# RE01_1500KB register map
Vendor: Renesas Electronics Corporation; Series: RE01_1500KB; File version: 1.20
CPU: CM0PLUS r0p1, little endian, MPU, no FPU, VTOR, 2 interrupt priority bits
Registers are 8-bit, read-write, reset 0x0 unless marked. A register's access mark holds for its fields unless they carry their own. Offsets are from the block's base; [hi:lo] are bit positions; {n}, {i} and the like mark numbered series; 'fields as' and 'values as' point back to an identical list; <NAME> marks a mode.

## GPT162 — General PWM Timer 2 (16-bit)
Base 0x40055200
Same registers: GPT163 0x40055300, GPT164 0x40055400, GPT165 0x40055500
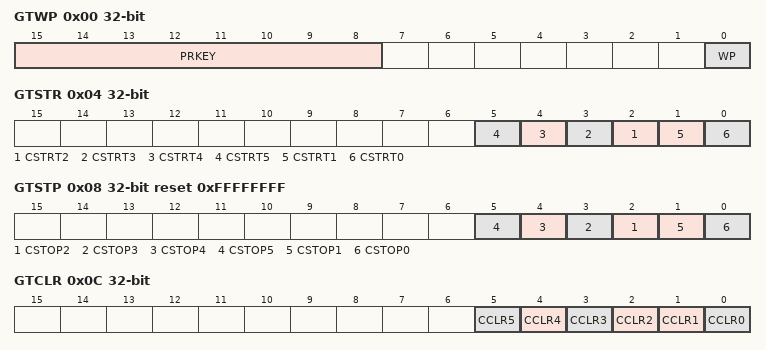
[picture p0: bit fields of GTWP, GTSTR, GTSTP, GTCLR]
0x00 GTWP 32-bit — General PWM Timer Write-Protection Register
  [15:8] PRKEY wo — GTWP Key Code
    165=Written to these bits, the WP bits write is permitted; other=others (The WP bits write is not permitted.)
  [0] WP — Register Write Disable
    0=Write to the register is enabled; 1=Write to the register is disabled
0x04 GTSTR 32-bit — General PWM Timer Software Start Register
  [n] CSTRT{n} (n=2..5) — Channel {n} GTCNT Count StartRead data shows each channel's counter status (GTCR.CST bit). 0 means counter stop. 1 means counter running.
    0=No effect (write) / counter stop (read); 1=GPT{n+160}.GTCNT counter starts (write) / Counter running (read)
  [1] CSTRT1 — Channel 1 GTCNT Count StartRead data shows each channel's counter status (GTCR.CST bit). 0 means counter stop. 1 means counter running.
    0=No effect (write) / counter stop (read); 1=GPT321.GTCNT counter starts (write) / Counter running (read)
  [0] CSTRT0 — Channel 0 GTCNT Count StartRead data shows each channel's counter status (GTCR.CST bit). 0 means counter stop. 1 means counter running.
    0=No effect (write) / counter stop (read); 1=GPT320.GTCNT counter starts (write) / Counter running (read)
0x08 GTSTP 32-bit reset 0xFFFFFFFF — General PWM Timer Software Stop Register
  [n] CSTOP{n} (n=2..5) — Channel {n} GTCNT Count StopRead data shows each channel's counter status (GTCR.CST bit). 0 means counter runnning. 1 means counter stop.
    0=No effect (write) / counter running (read); 1=GPT{n+160}.GTCNT counter stops (write) / Counter stop (read)
  [1] CSTOP1 — Channel 1 GTCNT Count StopRead data shows each channel's counter status (GTCR.CST bit). 0 means counter runnning. 1 means counter stop.
    0=No effect (write) / counter running (read); 1=GPT321.GTCNT counter stops (write) / Counter stop (read)
  [0] CSTOP0 — Channel 0 GTCNT Count StopRead data shows each channel's counter status (GTCR.CST bit). 0 means counter runnning. 1 means counter stop.
    0=No effect (write) / counter running (read); 1=GPT320.GTCNT counter stops (write) / Counter stop (read)
0x0C GTCLR 32-bit wo — General PWM Timer Software Clear Register
  [n] CCLR{n} (n=2..5) — Channel {n} GTCNT Count Clear
    0=No effect; 1=GPT{n+160}.GTCNT counter clears
  [1] CCLR1 — Channel 1 GTCNT Count Clear
    0=No effect; 1=GPT321.GTCNT counter clears
  [0] CCLR0 — Channel 0 GTCNT Count Clear
    0=No effect; 1=GPT320.GTCNT counter clears
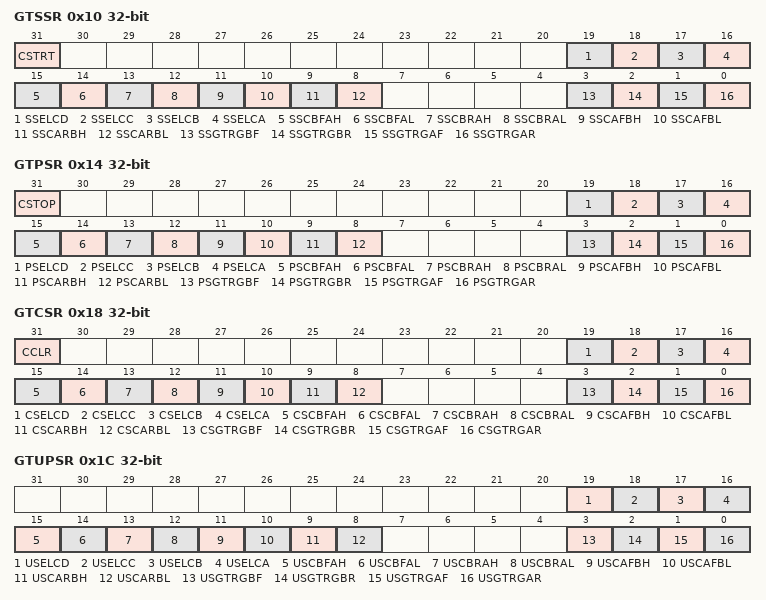
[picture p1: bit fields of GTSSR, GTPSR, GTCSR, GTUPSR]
0x10 GTSSR 32-bit — General PWM Timer Start Source Select Register
  [31] CSTRT — Software Source Counter Start Enable
    0=Counter start is disable by the GTSTR register; 1=Counter start is enable by the GTSTR register
  [19] SSELCD — ELCD Event Source Counter Start Enable
    0=Counter start is disable at the ELCD input; 1=Counter start is enable at the ELCD input
  [18] SSELCC — ELCC Event Source Counter Start Enable
    0=Counter start is disable at the ELCC input; 1=Counter start is enable at the ELCC input
  [17] SSELCB — ELCB Event Source Counter Start Enable
    0=Counter start is disable at the ELCB input; 1=Counter start is enable at the ELCB input
  [16] SSELCA — ELCA Event Source Counter Start Enable
    0=Counter start is disable at the ELCA input; 1=Counter start is enable at the ELCA input
  [15] SSCBFAH — GTIOCB Pin Falling Input during GTIOCA Value High Source Counter Start Enable
    0=Counter start is disable at the falling edge of GTIOCB input when GTIOCA input is 1; 1=Counter start is enable at the falling edge of GTIOCB input when GTIOCA input is 1
  [14] SSCBFAL — GTIOCB Pin Falling Input during GTIOCA Value Low Source Counter Start Enable
    0=Counter start is disable at the falling edge of GTIOCB input when GTIOCA input is 0; 1=Counter start is enable at the falling edge of GTIOCB input when GTIOCA input is 0
  [13] SSCBRAH — GTIOCB Pin Rising Input during GTIOCA Value High Source Counter Start Enable
    0=Counter start is disable at the rising edge of GTIOCB input when GTIOCA input is 1; 1=Counter start is enable at the rising edge of GTIOCB input when GTIOCA input is 1
  [12] SSCBRAL — GTIOCB Pin Rising Input during GTIOCA Value Low Source Counter Start Enable
    0=Counter start is disable at the rising edge of GTIOCB input when GTIOCA input is 0; 1=Counter start is enable at the rising edge of GTIOCB input when GTIOCA input is 0
  [11] SSCAFBH — GTIOCA Pin Falling Input during GTIOCB Value High Source Counter Start Enable
    0=Counter start is disable at the falling edge of GTIOCA input when GTIOCB input is 1; 1=Counter start is enable at the falling edge of GTIOCA input when GTIOCB input is 1
  [10] SSCAFBL — GTIOCA Pin Falling Input during GTIOCB Value Low Source Counter Start Enable
    0=Counter start is disable at the falling edge of GTIOCA input when GTIOCB input is 0; 1=Counter start is enable at the falling edge of GTIOCA input when GTIOCB input is 0
  [9] SSCARBH — GTIOCA Pin Rising Input during GTIOCB Value High Source Counter Start Enable
    0=Counter start is disable at the rising edge of GTIOCA input when GTIOCB input is 1; 1=Counter start is enable at the rising edge of GTIOCA input when GTIOCB input is 1
  [8] SSCARBL — GTIOCA Pin Rising Input during GTIOCB Value Low Source Counter Start Enable
    0=Counter start is disable at the rising edge of GTIOCA input when GTIOCB input is 0; 1=Counter start is enable at the rising edge of GTIOCA input when GTIOCB input is 0
  [3] SSGTRGBF — GTETRGB Pin Falling Input Source Counter Start Enable
    0=Counter start is disable at the falling edge of GTETRGB input; 1=Counter start is enable at the falling edge of GTETRGB input
  [2] SSGTRGBR — GTETRGB Pin Rising Input Source Counter Start Enable
    0=Counter start is disable at the rising edge of GTETRGB input; 1=Counter start is enable at the rising edge of GTETRGB input
  [1] SSGTRGAF — GTETRGA Pin Falling Input Source Counter Start Enable
    0=Counter start is disable at the falling edge of GTETRGA input; 1=Counter start is enable at the falling edge of GTETRGA input
  [0] SSGTRGAR — GTETRGA Pin Rising Input Source Counter Start Enable
    0=Counter start is disable at the rising edge of GTETRGA input; 1=Counter start is enable at the rising edge of GTETRGA input
0x14 GTPSR 32-bit — General PWM Timer Stop Source Select Register
  [31] CSTOP — Software Source Counter Stop Enable
    0=Counter stop is disable by the GTSTP register; 1=Counter stop is enable by the GTSTP register
  [19] PSELCD — ELCD Event Source Counter Stop Enable
    0=Counter stop is disable at the ELCD input; 1=Counter stop is enable at the ELCD input
  [18] PSELCC — ELCC Event Source Counter Stop Enable
    0=Counter stop is disable at the ELCC input; 1=Counter stop is enable at the ELCC input
  [17] PSELCB — ELCB Event Source Counter Stop Enable
    0=Counter stop is disable at the ELCB input; 1=Counter stop is enable at the ELCB input
  [16] PSELCA — ELCA Event Source Counter Stop Enable
    0=Counter stop is disable at the ELCA input; 1=Counter stop is enable at the ELCA input
  [15] PSCBFAH — GTIOCB Pin Falling Input during GTIOCA Value High Source Counter Stop Enable
    0=Counter stop is disable at the falling edge of GTIOCB input when GTIOCA input is 1; 1=Counter stop is enable at the falling edge of GTIOCB input when GTIOCA input is 1
  [14] PSCBFAL — GTIOCB Pin Falling Input during GTIOCA Value Low Source Counter Stop Enable
    0=Counter stop is disable at the falling edge of GTIOCB input when GTIOCA input is 0; 1=Counter stop is enable at the falling edge of GTIOCB input when GTIOCA input is 0
  [13] PSCBRAH — GTIOCB Pin Rising Input during GTIOCA Value High Source Counter Stop Enable
    0=Counter stop is disable at the rising edge of GTIOCB input when GTIOCA input is 1; 1=Counter stop is enable at the rising edge of GTIOCB input when GTIOCA input is 1
  [12] PSCBRAL — GTIOCB Pin Rising Input during GTIOCA Value Low Source Counter Stop Enable
    0=Counter stop is disable at the rising edge of GTIOCB input when GTIOCA input is 0; 1=Counter stop is enable at the rising edge of GTIOCB input when GTIOCA input is 0
  [11] PSCAFBH — GTIOCA Pin Falling Input during GTIOCB Value High Source Counter Stop Enable
    0=Counter stop is disable at the falling edge of GTIOCA input when GTIOCB input is 1; 1=Counter stop is enable at the falling edge of GTIOCA input when GTIOCB input is 1
  [10] PSCAFBL — GTIOCA Pin Falling Input during GTIOCB Value Low Source Counter Stop Enable
    0=Counter stop is disable at the falling edge of GTIOCA input when GTIOCB input is 0; 1=Counter stop is enable at the falling edge of GTIOCA input when GTIOCB input is 0
  [9] PSCARBH — GTIOCA Pin Rising Input during GTIOCB Value High Source Counter Stop Enable
    0=Counter stop is disable at the rising edge of GTIOCA input when GTIOCB input is 1; 1=Counter stop is enable at the rising edge of GTIOCA input when GTIOCB input is 1
  [8] PSCARBL — GTIOCA Pin Rising Input during GTIOCB Value Low Source Counter Stop Enable
    0=Counter stop is disable at the rising edge of GTIOCA input when GTIOCB input is 0; 1=Counter stop is enable at the rising edge of GTIOCA input when GTIOCB input is 0
  [3] PSGTRGBF — GTETRGB Pin Falling Input Source Counter Stop Enable
    0=Counter stop is disable at the falling edge of GTETRGB input; 1=Counter stop is enable at the falling edge of GTETRGB input
  [2] PSGTRGBR — GTETRGB Pin Rising Input Source Counter Stop Enable
    0=Counter stop is disable at the rising edge of GTETRGB input; 1=Counter stop is enable at the rising edge of GTETRGB input
  [1] PSGTRGAF — GTETRGA Pin Falling Input Source Counter Stop Enable
    0=Counter stop is disable at the falling edge of GTETRGA input; 1=Counter stop is enable at the falling edge of GTETRGA input
  [0] PSGTRGAR — GTETRGA Pin Rising Input Source Counter Stop Enable
    0=Counter stop is disable at the rising edge of GTETRGA input; 1=Counter stop is enable at the rising edge of GTETRGA input
0x18 GTCSR 32-bit — General PWM Timer Clear Source Select Register
  [31] CCLR — Software Source Counter Clear Enable
    0=Counter clear is disable by the GTCLR register; 1=Counter clear is enable by the GTCLR register
  [19] CSELCD — ELCD Event Source Counter Clear Enable
    0=Counter clear is disable at the ELCD input; 1=Counter clear is enable at the ELCD input
  [18] CSELCC — ELCC Event Source Counter Clear Enable
    0=Counter clear is disable at the ELCC input; 1=Counter clear is enable at the ELCC input
  [17] CSELCB — ELCB Event Source Counter Clear Enable
    0=Counter clear is disable at the ELCB input; 1=Counter clear is enable at the ELCB input
  [16] CSELCA — ELCA Event Source Counter Clear Enable
    0=Counter clear is disable at the ELCA input; 1=Counter clear is enable at the ELCA input
  [15] CSCBFAH — GTIOCB Pin Falling Input during GTIOCA Value High Source Counter Clear Enable
    0=Counter clear is disable at the falling edge of GTIOCB input when GTIOCA input is 1; 1=Counter clear is enable at the falling edge of GTIOCB input when GTIOCA input is 1
  [14] CSCBFAL — GTIOCB Pin Falling Input during GTIOCA Value Low Source Counter Clear Enable
    0=Counter clear is disable at the falling edge of GTIOCB input when GTIOCA input is 0; 1=Counter clear is enable at the falling edge of GTIOCB input when GTIOCA input is 0
  [13] CSCBRAH — GTIOCB Pin Rising Input during GTIOCA Value High Source Counter Clear Enable
    0=Counter clear is disable at the rising edge of GTIOCB input when GTIOCA input is 1; 1=Counter clear is enable at the rising edge of GTIOCB input when GTIOCA input is 1
  [12] CSCBRAL — GTIOCB Pin Rising Input during GTIOCA Value Low Source Counter Clear Enable
    0=Counter clear is disable at the rising edge of GTIOCB input when GTIOCA input is 0; 1=Counter clear is enable at the rising edge of GTIOCB input when GTIOCA input is 0
  [11] CSCAFBH — GTIOCA Pin Falling Input during GTIOCB Value High Source Counter Clear Enable
    0=Counter clear is disable at the falling edge of GTIOCA input when GTIOCB input is 1; 1=Counter clear is enable at the falling edge of GTIOCA input when GTIOCB input is 1
  [10] CSCAFBL — GTIOCA Pin Falling Input during GTIOCB Value Low Source Counter Clear Enable
    0=Counter clear is disable at the falling edge of GTIOCA input when GTIOCB input is 0; 1=Counter clear is enable at the falling edge of GTIOCA input when GTIOCB input is 0
  [9] CSCARBH — GTIOCA Pin Rising Input during GTIOCB Value High Source Counter Clear Enable
    0=Counter clear is disable at the rising edge of GTIOCA input when GTIOCB input is 1; 1=Counter clear is enable at the rising edge of GTIOCA input when GTIOCB input is 1
  [8] CSCARBL — GTIOCA Pin Rising Input during GTIOCB Value Low Source Counter Clear Enable
    0=Counter clear is disable at the rising edge of GTIOCA input when GTIOCB input is 0; 1=Counter clear is enable at the rising edge of GTIOCA input when GTIOCB input is 0
  [3] CSGTRGBF — GTETRGB Pin Falling Input Source Counter Clear Enable
    0=Counter clear is disable at the falling edge of GTETRGB input; 1=Counter clear is enable at the falling edge of GTETRGB input
  [2] CSGTRGBR — GTETRGB Pin Rising Input Source Counter Clear Enable
    0=Counter clear is disable at the rising edge of GTETRGB input; 1=Counter clear is enable at the rising edge of GTETRGB input
  [1] CSGTRGAF — GTETRGA Pin Falling Input Source Counter Clear Enable
    0=Counter clear is disable at the falling edge of GTETRGA input; 1=Counter clear is enable at the falling edge of GTETRGA input
  [0] CSGTRGAR — GTETRGA Pin Rising Input Source Counter Clear Enable
    0=Counter clear is disable at the rising edge of GTETRGA input; 1=Counter clear is enable at the rising edge of GTETRGA input
0x1C GTUPSR 32-bit — General PWM Timer Up Count Source Select Register
  [19] USELCD — ELCD Event Source Counter Count Up Enable
    0=Counter count up is disable at the ELCD input; 1=Counter count up is enable at the ELCD input
  [18] USELCC — ELCC Event Source Counter Count Up Enable
    0=Counter count up is disable at the ELCC input; 1=Counter count up is enable at the ELCC input
  [17] USELCB — ELCB Event Source Counter Count Up Enable
    0=Counter count up is disable at the ELCB input; 1=Counter count up is enable at the ELCB input
  [16] USELCA — ELCA Event Source Counter Count Up Enable
    0=Counter count up is disable at the ELCA input; 1=Counter count up is enable at the ELCA input
  [15] USCBFAH — GTIOCB Pin Falling Input during GTIOCA Value High Source Counter Count Up Enable
    0=Counter count up is disable at the falling edge of GTIOCB input when GTIOCA input is 1; 1=Counter count up is enable at the falling edge of GTIOCB input when GTIOCA input is 1
  [14] USCBFAL — GTIOCB Pin Falling Input during GTIOCA Value Low Source Counter Count Up Enable
    0=Counter count up is disable at the falling edge of GTIOCB input when GTIOCA input is 0; 1=Counter count up is enable at the falling edge of GTIOCB input when GTIOCA input is 0
  [13] USCBRAH — GTIOCB Pin Rising Input during GTIOCA Value High Source Counter Count Up Enable
    0=Counter count up is disable at the rising edge of GTIOCB input when GTIOCA input is 1; 1=Counter count up is enable at the rising edge of GTIOCB input when GTIOCA input is 1
  [12] USCBRAL — GTIOCB Pin Rising Input during GTIOCA Value Low Source Counter Count Up Enable
    0=Counter count up is disable at the rising edge of GTIOCB input when GTIOCA input is 0; 1=Counter count up is enable at the rising edge of GTIOCB input when GTIOCA input is 0
  [11] USCAFBH — GTIOCA Pin Falling Input during GTIOCB Value High Source Counter Count Up Enable
    0=Counter count up is disable at the falling edge of GTIOCA input when GTIOCB input is 1; 1=Counter count up is enable at the falling edge of GTIOCA input when GTIOCB input is 1
  [10] USCAFBL — GTIOCA Pin Falling Input during GTIOCB Value Low Source Counter Count Up Enable
    0=Counter count up is disable at the falling edge of GTIOCA input when GTIOCB input is 0; 1=Counter count up is enable at the falling edge of GTIOCA input when GTIOCB input is 0
  [9] USCARBH — GTIOCA Pin Rising Input during GTIOCB Value High Source Counter Count Up Enable
    0=Counter count up is disable at the rising edge of GTIOCA input when GTIOCB input is 1; 1=Counter count up is enable at the rising edge of GTIOCA input when GTIOCB input is 1
  [8] USCARBL — GTIOCA Pin Rising Input during GTIOCB Value Low Source Counter Count Up Enable
    0=Counter count up is disable at the rising edge of GTIOCA input when GTIOCB input is 0; 1=Counter count up is enable at the rising edge of GTIOCA input when GTIOCB input is 0
  [3] USGTRGBF — GTETRGB Pin Falling Input Source Counter Count Up Enable
    0=Counter count up is disable at the falling edge of GTETRGB input; 1=Counter count up is enable at the falling edge of GTETRGB input
  [2] USGTRGBR — GTETRGB Pin Rising Input Source Counter Count Up Enable
    0=Counter count up is disable at the rising edge of GTETRGB input; 1=Counter count up is enable at the rising edge of GTETRGB input
  [1] USGTRGAF — GTETRGA Pin Falling Input Source Counter Count Up Enable
    0=Counter count up is disable at the falling edge of GTETRGA input; 1=Counter count up is enable at the falling edge of GTETRGA input
  [0] USGTRGAR — GTETRGA Pin Rising Input Source Counter Count Up Enable
    0=Counter count up is disable at the rising edge of GTETRGA input; 1=Counter count up is enable at the rising edge of GTETRGA input
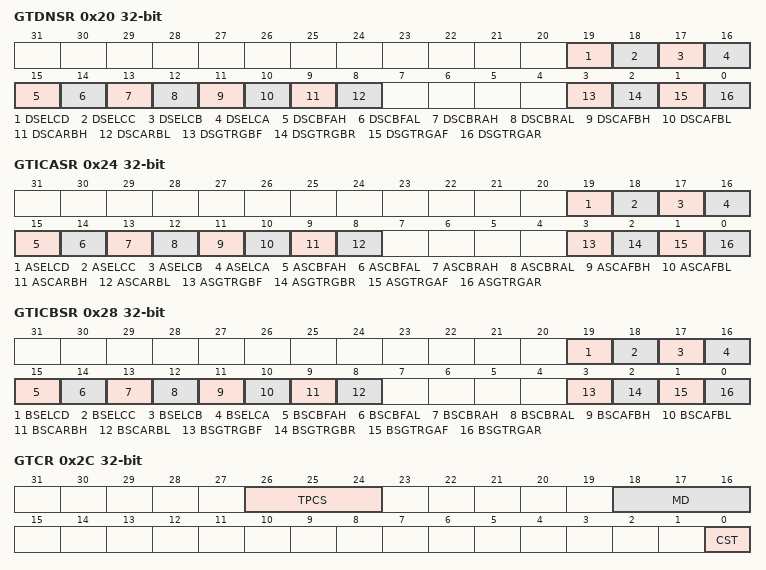
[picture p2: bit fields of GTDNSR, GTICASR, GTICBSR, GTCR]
0x20 GTDNSR 32-bit — General PWM Timer Down Count Source Select Register
  [19] DSELCD — ELCD Event Source Counter Count Down Enable
    0=Counter count down is disable at the ELCD input; 1=Counter count down is enable at the ELCD input
  [18] DSELCC — ELCC Event Source Counter Count Down Enable
    0=Counter count down is disable at the ELCC input; 1=Counter count down is enable at the ELCC input
  [17] DSELCB — ELCB Event Source Counter Count Down Enable
    0=Counter count down is disable at the ELCB input; 1=Counter count down is enable at the ELCB input
  [16] DSELCA — ELCA Event Source Counter Count Down Enable
    0=Counter count down is disable at the ELCA input; 1=Counter count down is enable at the ELCA input
  [15] DSCBFAH — GTIOCB Pin Falling Input during GTIOCA Value High Source Counter Count Down Enable
    0=Counter count down is disable at the falling edge of GTIOCB input when GTIOCA input is 1; 1=Counter count down is enable at the falling edge of GTIOCB input when GTIOCA input is 1
  [14] DSCBFAL — GTIOCB Pin Falling Input during GTIOCA Value Low Source Counter Count Down Enable
    0=Counter count down is disable at the falling edge of GTIOCB input when GTIOCA input is 0; 1=Counter count down is enable at the falling edge of GTIOCB input when GTIOCA input is 0
  [13] DSCBRAH — GTIOCB Pin Rising Input during GTIOCA Value High Source Counter Count Down Enable
    0=Counter count down is disable at the rising edge of GTIOCB input when GTIOCA input is 1; 1=Counter count down is enable at the rising edge of GTIOCB input when GTIOCA input is 1
  [12] DSCBRAL — GTIOCB Pin Rising Input during GTIOCA Value Low Source Counter Count Down Enable
    0=Counter count down is disable at the rising edge of GTIOCB input when GTIOCA input is 0; 1=Counter count down is enable at the rising edge of GTIOCB input when GTIOCA input is 0
  [11] DSCAFBH — GTIOCA Pin Falling Input during GTIOCB Value High Source Counter Count Down Enable
    0=Counter count down is disable at the falling edge of GTIOCA input when GTIOCB input is 1; 1=Counter count down is enable at the falling edge of GTIOCA input when GTIOCB input is 1
  [10] DSCAFBL — GTIOCA Pin Falling Input during GTIOCB Value Low Source Counter Count Down Enable
    0=Counter count down is disable at the falling edge of GTIOCA input when GTIOCB input is 0; 1=Counter count down is enable at the falling edge of GTIOCA input when GTIOCB input is 0
  [9] DSCARBH — GTIOCA Pin Rising Input during GTIOCB Value High Source Counter Count Down Enable
    0=Counter count down is disable at the rising edge of GTIOCA input when GTIOCB input is 1; 1=Counter count down is enable at the rising edge of GTIOCA input when GTIOCB input is 1
  [8] DSCARBL — GTIOCA Pin Rising Input during GTIOCB Value Low Source Counter Count Down Enable
    0=Counter count down is disable at the rising edge of GTIOCA input when GTIOCB input is 0; 1=Counter count down is enable at the rising edge of GTIOCA input when GTIOCB input is 0
  [3] DSGTRGBF — GTETRGB Pin Falling Input Source Counter Count Down Enable
    0=Counter count down is disable at the falling edge of GTETRGB input; 1=Counter count down is enable at the falling edge of GTETRGB input
  [2] DSGTRGBR — GTETRGB Pin Rising Input Source Counter Count Down Enable
    0=Counter count down is disable at the rising edge of GTETRGB input; 1=Counter count down is enable at the rising edge of GTETRGB input
  [1] DSGTRGAF — GTETRGA Pin Falling Input Source Counter Count Down Enable
    0=Counter count down is disable at the falling edge of GTETRGA input; 1=Counter count down is enable at the falling edge of GTETRGA input
  [0] DSGTRGAR — GTETRGA Pin Rising Input Source Counter Count Down Enable
    0=Counter count down is disable at the rising edge of GTETRGA input; 1=Counter count down is enable at the rising edge of GTETRGA input
0x24 GTICASR 32-bit — General PWM Timer Input Capture Source Select Register A
  [19] ASELCD — ELCD Event Source GTCCRA Input Capture Enable
    0=GTCCRA input capture is disable at the ELCD input; 1=GTCCRA input capture is enable at the ELCD input
  [18] ASELCC — ELCC Event Source GTCCRA Input Capture Enable
    0=GTCCRA input capture is disable at the ELCC input; 1=GTCCRA input capture is enable at the ELCC input
  [17] ASELCB — ELCB Event Source GTCCRA Input Capture Enable
    0=GTCCRA input capture is disable at the ELCB input; 1=GTCCRA input capture is enable at the ELCB input
  [16] ASELCA — ELCA Event Source GTCCRA Input Capture Enable
    0=GTCCRA input capture is disable at the ELCA input; 1=GTCCRA input capture is enable at the ELCA input
  [15] ASCBFAH — GTIOCB Pin Falling Input during GTIOCA Value High Source GTCCRA Input Capture Enable
    0=GTCCRA input capture is disable at the falling edge of GTIOCB input when GTIOCA input is 1; 1=GTCCRA input capture is enable at the falling edge of GTIOCB input when GTIOCA input is 1
  [14] ASCBFAL — GTIOCB Pin Falling Input during GTIOCA Value Low Source GTCCRA Input Capture Enable
    0=GTCCRA input capture is disable at the falling edge of GTIOCB input when GTIOCA input is 0; 1=GTCCRA input capture is enable at the falling edge of GTIOCB input when GTIOCA input is 0
  [13] ASCBRAH — GTIOCB Pin Rising Input during GTIOCA Value High Source GTCCRA Input Capture Enable
    0=GTCCRA input capture is disable at the rising edge of GTIOCB input when GTIOCA input is 1; 1=GTCCRA input capture is enable at the rising edge of GTIOCB input when GTIOCA input is 1
  [12] ASCBRAL — GTIOCB Pin Rising Input during GTIOCA Value Low Source GTCCRA Input Capture Enable
    0=GTCCRA input capture is disable at the rising edge of GTIOCB input when GTIOCA input is 0; 1=GTCCRA input capture is enable at the rising edge of GTIOCB input when GTIOCA input is 0
  [11] ASCAFBH — GTIOCA Pin Falling Input during GTIOCB Value High Source GTCCRA Input Capture Enable
    0=GTCCRA input capture is disable at the falling edge of GTIOCA input when GTIOCB input is 1; 1=GTCCRA input capture is enable at the falling edge of GTIOCA input when GTIOCB input is 1
  [10] ASCAFBL — GTIOCA Pin Falling Input during GTIOCB Value Low Source GTCCRA Input Capture Enable
    0=GTCCRA input capture is disable at the falling edge of GTIOCA input when GTIOCB input is 0; 1=GTCCRA input capture is enable at the falling edge of GTIOCA input when GTIOCB input is 0
  [9] ASCARBH — GTIOCA Pin Rising Input during GTIOCB Value High Source GTCCRA Input Capture Enable
    0=GTCCRA input capture is disable at the rising edge of GTIOCA input when GTIOCB input is 1; 1=GTCCRA input capture is enable at the rising edge of GTIOCA input when GTIOCB input is 1
  [8] ASCARBL — GTIOCA Pin Rising Input during GTIOCB Value Low Source GTCCRA Input Capture Enable
    0=GTCCRA input capture is disable at the rising edge of GTIOCA input when GTIOCB input is 0; 1=GTCCRA input capture is enable at the rising edge of GTIOCA input when GTIOCB input is 0
  [3] ASGTRGBF — GTETRGB Pin Falling Input Source GTCCRA Input Capture Enable
    0=GTCCRA input capture is disable at the falling edge of GTETRGB input; 1=GTCCRA input capture is enable at the falling edge of GTETRGB input
  [2] ASGTRGBR — GTETRGB Pin Rising Input Source GTCCRA Input Capture Enable
    0=GTCCRA input capture is disable at the rising edge of GTETRGB input; 1=GTCCRA input capture is enable at the rising edge of GTETRGB input
  [1] ASGTRGAF — GTETRGA Pin Falling Input Source GTCCRA Input Capture Enable
    0=GTCCRA input capture is disable at the falling edge of GTETRGA input; 1=GTCCRA input capture is enable at the falling edge of GTETRGA input
  [0] ASGTRGAR — GTETRGA Pin Rising Input Source GTCCRA Input Capture Enable
    0=GTCCRA input capture is disable at the rising edge of GTETRGA input; 1=GTCCRA input capture is enable at the rising edge of GTETRGA input
0x28 GTICBSR 32-bit — General PWM Timer Input Capture Source Select Register B
  [19] BSELCD — ELCD Event Source GTCCRB Input Capture Enable
    0=GTCCRB input capture is disable at the ELCD input; 1=GTCCRB input capture is enable at the ELCD input
  [18] BSELCC — ELCC Event Source GTCCRB Input Capture Enable
    0=GTCCRB input capture is disable at the ELCC input; 1=GTCCRB input capture is enable at the ELCC input
  [17] BSELCB — ELCB Event Source GTCCRB Input Capture Enable
    0=GTCCRB input capture is disable at the ELCB input; 1=GTCCRB input capture is enable at the ELCB input
  [16] BSELCA — ELCA Event Source GTCCRB Input Capture Enable
    0=GTCCRB input capture is disable at the ELCA input; 1=GTCCRB input capture is enable at the ELCA input
  [15] BSCBFAH — GTIOCB Pin Falling Input during GTIOCA Value High Source GTCCRB Input Capture Enable
    0=GTCCRB input capture is disable at the falling edge of GTIOCB input when GTIOCA input is 1; 1=GTCCRB input capture is enable at the falling edge of GTIOCB input when GTIOCA input is 1
  [14] BSCBFAL — GTIOCB Pin Falling Input during GTIOCA Value Low Source GTCCRB Input Capture Enable
    0=GTCCRB input capture is disable at the falling edge of GTIOCB input when GTIOCA input is 0; 1=GTCCRB input capture is enable at the falling edge of GTIOCB input when GTIOCA input is 0
  [13] BSCBRAH — GTIOCB Pin Rising Input during GTIOCA Value High Source GTCCRB Input Capture Enable
    0=GTCCRB input capture is disable at the rising edge of GTIOCB input when GTIOCA input is 1; 1=GTCCRB input capture is enable at the rising edge of GTIOCB input when GTIOCA input is 1
  [12] BSCBRAL — GTIOCB Pin Rising Input during GTIOCA Value Low Source GTCCRB Input Capture Enable
    0=GTCCRB input capture is disable at the rising edge of GTIOCB input when GTIOCA input is 0; 1=GTCCRB input capture is enable at the rising edge of GTIOCB input when GTIOCA input is 0
  [11] BSCAFBH — GTIOCA Pin Falling Input during GTIOCB Value High Source GTCCRB Input Capture Enable
    0=GTCCRB input capture is disable at the falling edge of GTIOCA input when GTIOCB input is 1; 1=GTCCRB input capture is enable at the falling edge of GTIOCA input when GTIOCB input is 1
  [10] BSCAFBL — GTIOCA Pin Falling Input during GTIOCB Value Low Source GTCCRB Input Capture Enable
    0=GTCCRB input capture is disable at the falling edge of GTIOCA input when GTIOCB input is 0; 1=GTCCRB input capture is enable at the falling edge of GTIOCA input when GTIOCB input is 0
  [9] BSCARBH — GTIOCA Pin Rising Input during GTIOCB Value High Source GTCCRB Input Capture Enable
    0=GTCCRB input capture is disable at the rising edge of GTIOCA input when GTIOCB input is 1; 1=GTCCRB input capture is enable at the rising edge of GTIOCA input when GTIOCB input is 1
  [8] BSCARBL — GTIOCA Pin Rising Input during GTIOCB Value Low Source GTCCRB Input Capture Enable
    0=GTCCRB input capture is disable at the rising edge of GTIOCA input when GTIOCB input is 0; 1=GTCCRB input capture is enable at the rising edge of GTIOCA input when GTIOCB input is 0
  [3] BSGTRGBF — GTETRGB Pin Falling Input Source GTCCRB Input Capture Enable
    0=GTCCRB input capture is disable at the falling edge of GTETRGB input; 1=GTCCRB input capture is enable at the falling edge of GTETRGB input
  [2] BSGTRGBR — GTETRGB Pin Rising Input Source GTCCRB Input Capture Enable
    0=GTCCRB input capture is disable at the rising edge of GTETRGB input; 1=GTCCRB input capture is enable at the rising edge of GTETRGB input
  [1] BSGTRGAF — GTETRGA Pin Falling Input Source GTCCRB Input Capture Enable
    0=GTCCRB input capture is disable at the falling edge of GTETRGA input; 1=GTCCRB input capture is enable at the falling edge of GTETRGA input
  [0] BSGTRGAR — GTETRGA Pin Rising Input Source GTCCRB Input Capture Enable
    0=GTCCRB input capture is disable at the rising edge of GTETRGA input; 1=GTCCRB input capture is enable at the rising edge of GTETRGA input
0x2C GTCR 32-bit — General PWM Timer Control Register
  [26:24] TPCS — Timer Prescaler Select
    0=PCLKD/1; 1=PCLKD/4; 2=PCLKD/16; 3=PCLKD/64; 4=PCLKD/256; 5=PCLKD/1024; other=others (Setting prohibied)
  [18:16] MD — Mode Select
    0=Saw-wave PWM mode (single buffer or double buffer possible); 1=Saw-wave one-shot pulse mode (fixed buffer operation); 2=Setting prohibited; 3=Setting prohibited; 4=Triangle-wave PWM mode 1 (32-bit transfer at crest) (single buffer or double buffer possible); 5=Triangle-wave PWM mode 2 (32-bit transfer at crest and trough) (single buffer or double buffer possible); 6=Triangle-wave PWM mode 3 (64-bit transfer at trough) fixed buffer operation); 7=Setting prohibited
  [0] CST — Count Start
    0=Count operation is stopped; 1=Count operation is performed
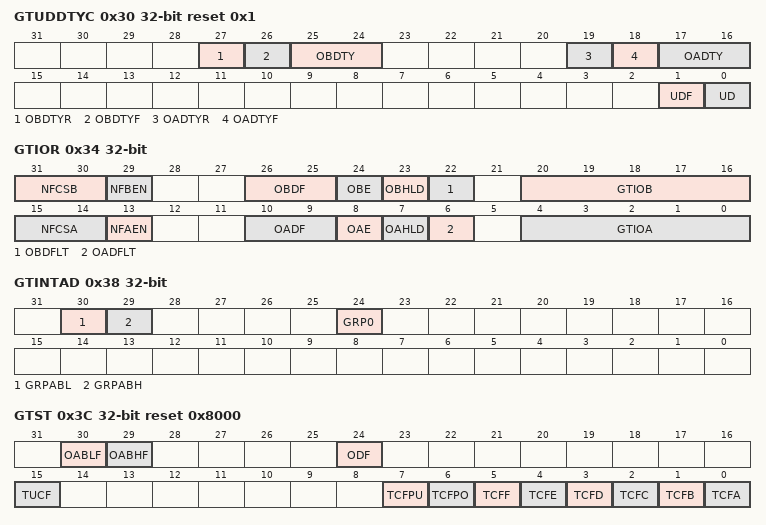
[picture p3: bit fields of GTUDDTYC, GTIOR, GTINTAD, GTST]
0x30 GTUDDTYC 32-bit reset 0x1 — General PWM Timer Count Direction and Duty Setting Register
  [27] OBDTYR — GTIOCB Output Value Selecting after Releasing 0 percent/100 percent Duty Setting
    0=Apply output value set in 0 percent/100 percent duty to GTIOB[3:2] function after releasing 0 percent/100 percent duty setting; 1=Apply masked compare match output value to GTIOB[3:2] function after releasing 0 percent/100 percent duty setting
  [26] OBDTYF — Forcible GTIOCB Output Duty Setting
    0=Not forcibly set; 1=Forcibly set
  [25:24] OBDTY — GTIOCB Output Duty Setting
    0=GTIOCB pin duty is depend on compare match; 1=GTIOCB pin duty is depend on compare match; 2=GTIOCB pin duty 0 percent; 3=GTIOCB pin duty 100 percent
  [19] OADTYR — GTIOCA Output Value Selecting after Releasing 0 percent/100 percent Duty Setting
    0=Apply output value set in 0 percent/100 percent duty to GTIOA[3:2] function after releasing 0 percent/100 percent duty setting; 1=Apply masked compare match output value to GTIOA[3:2] function after releasing 0 percent/100 percent duty setting
  [18] OADTYF — Forcible GTIOCA Output Duty Setting
    0=Not forcibly set; 1=Forcibly set
  [17:16] OADTY — GTIOCA Output Duty Setting
    0=GTIOCA pin duty is depend on compare match; 1=GTIOCA pin duty is depend on compare match; 2=GTIOCA pin duty 0 percent; 3=GTIOCA pin duty 100 percent
  [1] UDF — Forcible Count Direction Setting
    0=Not forcibly set; 1=Forcibly set
  [0] UD — Count Direction Setting
    0=GTCNT counts down; 1=GTCNT counts up
0x34 GTIOR 32-bit — General PWM Timer I/O Control Register
  [31:30] NFCSB — Noise Filter B Sampling Clock Select
    0=PCLKD/1; 1=PCLKD/4; 2=PCLKD/16; 3=PCLKD/64
  [29] NFBEN — Noise Filter B Enable
    0=The noise filter for the GTIOCB pin is disabled; 1=The noise filter for the GTIOCB pin is enabled
  [26:25] OBDF — GTIOCB Pin Disable Value Setting
    0=Output disable is prohibited; 1=GTIOCB pin is set to Hi-Z when output disable is performed; 2=GTIOCB pin is set to 0 when output disable is performed; 3=GTIOCB pin is set to 1 when output disable is performed
  [24] OBE — GTIOCB Pin Output Enable
    0=Output is disabled; 1=Output is enabled
  [23] OBHLD — GTIOCB Pin Output Setting at the Start/Stop Count
    0=The GTIOCB pin output level at start/stop of counting depends on the register setting; 1=The GTIOCB pin output level is retained at start/stop of counting
  [22] OBDFLT — GTIOCB Pin Output Value Setting at the Count Stop
    0=The GTIOCB pin outputs low when counting is stopped; 1=The GTIOCB pin outputs high when counting is stopped
  [20:16] GTIOB — GTIOCB Pin Function Select
    0=Initial output is Low. Output retained at cycle end. Output retained at GTCCRB compare match.; 1=Initial output is Low. Output retained at cycle end. Low output at GTCCRB compare match.; 2=Initial output is Low. Output retained at cycle end. High output at GTCCRB compare match.; 3=Initial output is Low. Output retained at cycle end. Output toggled at GTCCRB compare match.; 4=Initial output is Low. Low output at cycle end. Output retained at GTCCRB compare match.; 5=Initial output is Low. Low output at cycle end. Low output at GTCCRB compare match.; 6=Initial output is Low. Low output at cycle end. High output at GTCCRB compare match.; 7=Initial output is Low. Low output at cycle end. Output toggled at GTCCRB compare match.; 8=Initial output is Low. High output at cycle end. Output retained at GTCCRB compare match.; 9=Initial output is Low. High output at cycle end. Low output at GTCCRB compare match.; 10=Initial output is Low. High output at cycle end. High output at GTCCRB compare match.; 11=Initial output is Low. High output at cycle end. Output toggled at GTCCRB compare match.; 12=Initial output is Low. Output toggled at cycle end. Output retained at GTCCRB compare match.; 13=Initial output is Low. Output toggled at cycle end. Low output at GTCCRB compare match.; 14=Initial output is Low. Output toggled at cycle end. High output at GTCCRB compare match.; 15=Initial output is Low. Output toggled at cycle end. Output toggled at GTCCRB compare match.; 16=Initial output is High. Output retained at cycle end. Output retained at GTCCRB compare match.; 17=Initial output is High. Output retained at cycle end. Low output at GTCCRB compare match.; 18=Initial output is High. Output retained at cycle end. High output at GTCCRB compare match.; 19=Initial output is High. Output retained at cycle end. Output toggled at GTCCRB compare match.; 20=Initial output is High. Low output at cycle end. Output retained at GTCCRB compare match.; 21=Initial output is High. Low output at cycle end. Low output at GTCCRB compare match.; 22=Initial output is High. Low output at cycle end. High output at GTCCRB compare match.; 23=Initial output is High. Low output at cycle end. Output toggled at GTCCRB compare match.; 24=Initial output is High. High output at cycle end. Output retained at GTCCRB compare match.; 25=Initial output is High. High output at cycle end. Low output at GTCCRB compare match.; 26=Initial output is High. High output at cycle end. High output at GTCCRB compare match.; 27=Initial output is High. High output at cycle end. Output toggled at GTCCRB compare match.; 28=Initial output is High. Output toggled at cycle end. Output retained at GTCCRB compare match.; 29=Initial output is High. Output toggled at cycle end. Low output at GTCCRB compare match.; 30=Initial output is High. Output toggled at cycle end. High output at GTCCRB compare match.; 31=Initial output is High. Output toggled at cycle end. Output toggled at GTCCRB compare match.
  [15:14] NFCSA — Noise Filter A Sampling Clock Select
    0=PCLKD/1; 1=PCLKD/4; 2=PCLKD/16; 3=PCLKD/64
  [13] NFAEN — Noise Filter A Enable
    0=The noise filter for the GTIOCA pin is disabled; 1=The noise filter for the GTIOCA pin is enabled
  [10:9] OADF — GTIOCA Pin Disable Value Setting
    0=Output disable is prohibited; 1=GTIOCA pin is set to Hi-Z when output disable is performed; 2=GTIOCA pin is set to 0 when output disable is performed; 3=GTIOCA pin is set to 1 when output disable is performed
  [8] OAE — GTIOCA Pin Output Enable
    0=Output is disabled; 1=Output is enabled
  [7] OAHLD — GTIOCA Pin Output Setting at the Start/Stop Count
    0=The GTIOCA pin output level at start/stop of counting depends on the register setting; 1=The GTIOCA pin output level is retained at start/stop of counting
  [6] OADFLT — GTIOCA Pin Output Value Setting at the Count Stop
    0=The GTIOCA pin outputs low when counting is stopped; 1=The GTIOCA pin outputs high when counting is stopped
  [4:0] GTIOA — GTIOCA Pin Function Select
    0=Initial output is Low. Output retained at cycle end. Output retained at GTCCRA compare match.; 1=Initial output is Low. Output retained at cycle end. Low output at GTCCRA compare match.; 2=Initial output is Low. Output retained at cycle end. High output at GTCCRA compare match.; 3=Initial output is Low. Output retained at cycle end. Output toggled at GTCCRA compare match.; 4=Initial output is Low. Low output at cycle end. Output retained at GTCCRA compare match.; 5=Initial output is Low. Low output at cycle end. Low output at GTCCRA compare match.; 6=Initial output is Low. Low output at cycle end. High output at GTCCRA compare match.; 7=Initial output is Low. Low output at cycle end. Output toggled at GTCCRA compare match.; 8=Initial output is Low. High output at cycle end. Output retained at GTCCRA compare match.; 9=Initial output is Low. High output at cycle end. Low output at GTCCRA compare match.; 10=Initial output is Low. High output at cycle end. High output at GTCCRA compare match.; 11=Initial output is Low. High output at cycle end. Output toggled at GTCCRA compare match.; 12=Initial output is Low. Output toggled at cycle end. Output retained at GTCCRA compare match.; 13=Initial output is Low. Output toggled at cycle end. Low output at GTCCRA compare match.; 14=Initial output is Low. Output toggled at cycle end. High output at GTCCRA compare match.; 15=Initial output is Low. Output toggled at cycle end. Output toggled at GTCCRA compare match.; 16=Initial output is High. Output retained at cycle end. Output retained at GTCCRA compare match.; 17=Initial output is High. Output retained at cycle end. Low output at GTCCRA compare match.; 18=Initial output is High. Output retained at cycle end. High output at GTCCRA compare match.; 19=Initial output is High. Output retained at cycle end. Output toggled at GTCCRA compare match.; 20=Initial output is High. Low output at cycle end. Output retained at GTCCRA compare match.; 21=Initial output is High. Low output at cycle end. Low output at GTCCRA compare match.; 22=Initial output is High. Low output at cycle end. High output at GTCCRA compare match.; 23=Initial output is High. Low output at cycle end. Output toggled at GTCCRA compare match.; 24=Initial output is High. High output at cycle end. Output retained at GTCCRA compare match.; 25=Initial output is High. High output at cycle end. Low output at GTCCRA compare match.; 26=Initial output is High. High output at cycle end. High output at GTCCRA compare match.; 27=Initial output is High. High output at cycle end. Output toggled at GTCCRA compare match.; 28=Initial output is High. Output toggled at cycle end. Output retained at GTCCRA compare match.; 29=Initial output is High. Output toggled at cycle end. Low output at GTCCRA compare match.; 30=Initial output is High. Output toggled at cycle end. High output at GTCCRA compare match.; 31=Initial output is High. Output toggled at cycle end. Output toggled at GTCCRA compare match.
0x38 GTINTAD 32-bit — General PWM Timer Interrupt Output Setting Register
  [30] GRPABL — Same Time Output Level Low Disable Request Enable
    0=Same time output level low disable request is disabled; 1=Same time output level low disable request is enabled
  [29] GRPABH — Same Time Output Level High Disable Request Enable
    0=Same time output level high disable request is disabled; 1=Same time output level high disable request is enabled
  [24] GRP0 — Output Disable Source Select
    0=Group A output disable request; 1=Group B output disable request
0x3C GTST 32-bit reset 0x8000 — General PWM Timer Status Register
  [30] OABLF ro — Same Time Output Level Low Disable Request Enable
    0=GTIOCA pin and GTIOCB pin don't output 0 at the same time; 1=GTIOCA pin and GTIOCB pin output 0 at the same time
  [29] OABHF ro — Same Time Output Level High Disable Request Enable
    0=GTIOCA pin and GTIOCB pin don't output 1 at the same time; 1=GTIOCA pin and GTIOCB pin output 1 at the same time
  [24] ODF ro — Output Disable Flag
    0=No output disable request is generated; 1=An output disable request is generated
  [15] TUCF ro — Count Direction Flag
    0=The GTCNT counter counts downward; 1=The GTCNT counter counts upward
  [7] TCFPU — Underflow Flag
    0=No underflow (trough) has occurred; 1=An underflow (trough) has occurred
  [6] TCFPO — Overflow Flag
    0=No overflow (crest) has occurred; 1=An overflow (crest) has occurred
  [5] TCFF — Input Compare Match Flag F
    0=No compare match; 1=A compare match
  [4] TCFE — Input Compare Match Flag E
    0=No compare match; 1=A compare match
  [3] TCFD — Input Compare Match Flag D
    0=No compare match of GTCCRD is generated; 1=A compare match of GTCCRD is generated
  [2] TCFC — Input Compare Match Flag C
    0=No compare match of GTCCRC is generated; 1=A compare match of GTCCRC is generated
  [1] TCFB — Input Capture/Compare Match Flag B
    0=No input capture/compare match of GTCCRB is generated; 1=An input capture/compare match of GTCCRB is generated
  [0] TCFA — Input Capture/Compare Match Flag A
    0=No input capture/compare match of GTCCRA is generated; 1=An input capture/compare match of GTCCRA is generated
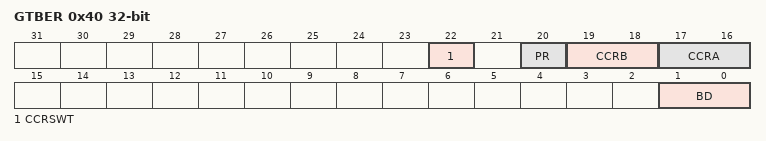
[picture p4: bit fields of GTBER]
0x40 GTBER 32-bit — General PWM Timer Buffer Enable Register
  [22] CCRSWT — GTCCRA and GTCCRB Forcible Buffer OperationThis bit is read as 0.
    0=no effect; 1=Forcibly performs buffer transfer of GTCCRA and GTCCRB. This bit automatically returns to 0 after the writing of 1.
  [20] PR — GTPR Buffer Operation
    0=Buffer operation is not performed; 1=Single buffer operation (GTPBR --> GTPR)
  [19:18] CCRB — GTCCRB Buffer Operation
    0=Buffer operation is not performed; 1=Single buffer operation (GTCCRB <--> GTCCRE); 2=Double buffer operation (GTCCRB <--> GTCCRE <--> GTCCRF); 3=Double buffer operation (GTCCRB <--> GTCCRE <--> GTCCRF)
  [17:16] CCRA — GTCCRA Buffer Operation
    0=Buffer operation is not performed; 1=Single buffer operation (GTCCRA <--> GTCCRC); 2=Double buffer operation (GTCCRA <--> GTCCRC <--> GTCCRD); 3=Double buffer operation (GTCCRA <--> GTCCRC <--> GTCCRD)
  [1:0] BD — BD[1]: GTPR Buffer Operation DisableBD[0]: GTCCR Buffer Operation Disable
    0=GTPR Buffer operation is enabled/GTCCR Buffer operation is enabled; 1=GTPR Buffer operation is enabled/GTCCR Buffer operation is disabled; 2=GTPR Buffer operation is disabled/GTCCR Buffer operation is enabled; 3=GTPR Buffer operation is disabled/GTCCR Buffer operation is enabled
0x48 GTCNT 32-bit — General PWM Timer Counter
  [31:0] GTCNT — Counter
0x4C GTCCRA 32-bit reset 0xFFFF — General PWM Timer Compare Capture Register A
  [15:0] GTCCRA — Compare Capture Register A
0x50 GTCCRB 32-bit reset 0xFFFF — General PWM Timer Compare Capture Register B
  [15:0] GTCCRB — Compare Capture Register B
0x54 GTCCRC 32-bit reset 0xFFFF — General PWM Timer Compare Capture Register C
  [15:0] GTCCRC — Compare Capture Register C
0x58 GTCCRE 32-bit reset 0xFFFF — General PWM Timer Compare Capture Register E
  [15:0] GTCCRE — Compare Capture Register E
0x5C GTCCRD 32-bit reset 0xFFFF — General PWM Timer Compare Capture Register D
  [15:0] GTCCRD — Compare Capture Register D
0x60 GTCCRF 32-bit reset 0xFFFF — General PWM Timer Compare Capture Register F
  [15:0] GTCCRF — Compare Capture Register F
0x64 GTPR 32-bit reset 0xFFFF — General PWM Timer Cycle Setting Register
  [15:0] GTPR — Cycle Setting Register
0x68 GTPBR 32-bit reset 0xFFFF — General PWM Timer Cycle Setting Buffer Register
  [15:0] GTPBR — Cycle Setting Buffer Register
0x88 GTDTCR 32-bit — General PWM Timer Dead Time Control Register
  [0] TDE — Negative-Phase Waveform Setting
    0=GTCCRB is set without using GTDVU; 1=GTDVU is used to set the compare match value for negative-phase waveform with dead time automatically in GTCCRB
0x8C GTDVU 32-bit reset 0xFFFF — General PWM Timer Dead Time Value Register U
  [15:0] GTDVU — Dead Time Value Register U

## GPT320 — General PWM Timer 0 (32-bit)
Base 0x40055000
Same registers: GPT321 0x40055100
Registers as GPT162; these are added or differ:
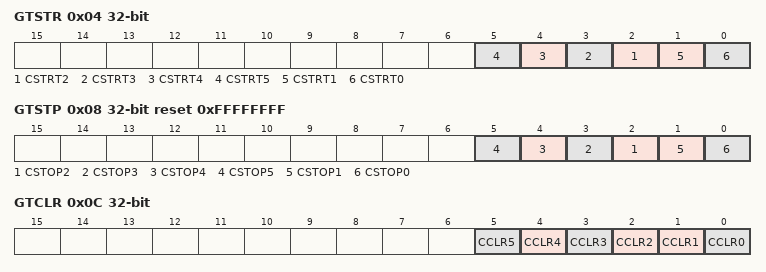
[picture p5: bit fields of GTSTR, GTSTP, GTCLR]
0x04 GTSTR 32-bit — General PWM Timer Software Start Register
  fields as GPT162.GTSTR
0x08 GTSTP 32-bit reset 0xFFFFFFFF — General PWM Timer Software Stop Register
  fields as GPT162.GTSTP
0x0C GTCLR 32-bit wo — General PWM Timer Software Clear Register
  fields as GPT162.GTCLR
0x4C GTCCRA 32-bit reset 0xFFFFFFFF — General PWM Timer Compare Capture Register A
  [31:0] GTCCRA — Compare Capture Register A
0x50 GTCCRB 32-bit reset 0xFFFFFFFF — General PWM Timer Compare Capture Register B
  [31:0] GTCCRB — Compare Capture Register B
0x54 GTCCRC 32-bit reset 0xFFFFFFFF — General PWM Timer Compare Capture Register C
  [31:0] GTCCRC — Compare Capture Register C
0x58 GTCCRE 32-bit reset 0xFFFFFFFF — General PWM Timer Compare Capture Register E
  [31:0] GTCCRE — Compare Capture Register E
0x5C GTCCRD 32-bit reset 0xFFFFFFFF — General PWM Timer Compare Capture Register D
  [31:0] GTCCRD — Compare Capture Register D
0x60 GTCCRF 32-bit reset 0xFFFFFFFF — General PWM Timer Compare Capture Register F
  [31:0] GTCCRF — Compare Capture Register F
0x64 GTPR 32-bit reset 0xFFFFFFFF — General PWM Timer Cycle Setting Register
  [31:0] GTPR — Cycle Setting Register
0x68 GTPBR 32-bit reset 0xFFFFFFFF — General PWM Timer Cycle Setting Buffer Register
  [31:0] GTPBR — Cycle Setting Buffer Register
0x8C GTDVU 32-bit reset 0xFFFFFFFF — General PWM Timer Dead Time Value Register U
  [31:0] GTDVU — Dead Time Value Register U
